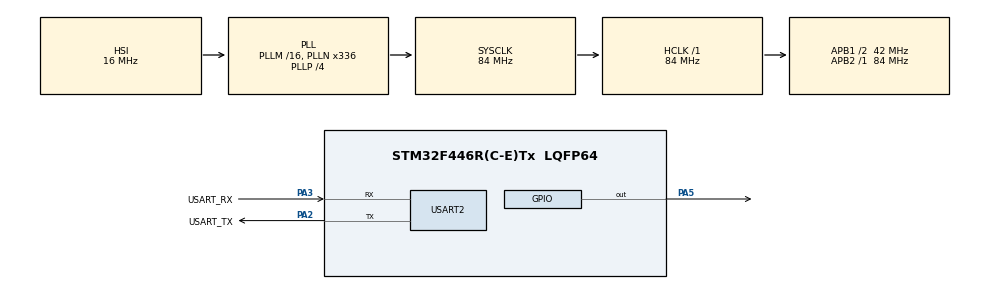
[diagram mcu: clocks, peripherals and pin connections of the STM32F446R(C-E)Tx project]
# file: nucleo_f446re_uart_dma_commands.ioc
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ADC1.Channel-0\#ChannelRegularConversion=ADC_CHANNEL_TEMPSENSOR
ADC1.DMAContinuousRequests=ENABLE
ADC1.ExternalTrigConv=ADC_EXTERNALTRIGCONV_T2_TRGO
ADC1.NbrOfConversionFlag=1
ADC1.Rank-0\#ChannelRegularConversion=1
ADC1.SamplingTime-0\#ChannelRegularConversion=ADC_SAMPLETIME_480CYCLES
ADC1.master=1
Dma.ADC1.2.Direction=DMA_PERIPH_TO_MEMORY
Dma.ADC1.2.FIFOMode=DMA_FIFOMODE_DISABLE
Dma.ADC1.2.Instance=DMA2_Stream0
Dma.ADC1.2.MemDataAlignment=DMA_MDATAALIGN_HALFWORD
Dma.ADC1.2.MemInc=DMA_MINC_ENABLE
Dma.ADC1.2.Mode=DMA_CIRCULAR
Dma.ADC1.2.PeriphDataAlignment=DMA_PDATAALIGN_HALFWORD
Dma.ADC1.2.PeriphInc=DMA_PINC_DISABLE
Dma.ADC1.2.Priority=DMA_PRIORITY_LOW
Dma.Request0=USART2_RX
Dma.Request1=USART2_TX
Dma.Request2=ADC1
Dma.USART2_RX.0.Direction=DMA_PERIPH_TO_MEMORY
Dma.USART2_RX.0.FIFOMode=DMA_FIFOMODE_DISABLE
Dma.USART2_RX.0.Instance=DMA1_Stream5
Dma.USART2_RX.0.MemDataAlignment=DMA_MDATAALIGN_BYTE
Dma.USART2_RX.0.MemInc=DMA_MINC_ENABLE
Dma.USART2_RX.0.Mode=DMA_CIRCULAR
Dma.USART2_RX.0.PeriphDataAlignment=DMA_PDATAALIGN_BYTE
Dma.USART2_RX.0.PeriphInc=DMA_PINC_DISABLE
Dma.USART2_RX.0.Priority=DMA_PRIORITY_HIGH
Dma.USART2_TX.1.Direction=DMA_MEMORY_TO_PERIPH
Dma.USART2_TX.1.FIFOMode=DMA_FIFOMODE_DISABLE
Dma.USART2_TX.1.Instance=DMA1_Stream6
Dma.USART2_TX.1.MemDataAlignment=DMA_MDATAALIGN_BYTE
Dma.USART2_TX.1.MemInc=DMA_MINC_ENABLE
Dma.USART2_TX.1.Mode=DMA_NORMAL
Dma.USART2_TX.1.PeriphDataAlignment=DMA_PDATAALIGN_BYTE
Dma.USART2_TX.1.PeriphInc=DMA_PINC_DISABLE
Dma.USART2_TX.1.Priority=DMA_PRIORITY_HIGH
FREERTOS.Mutexes01=sensorMutex,Dynamic,NULL,Available
FREERTOS.Queues01=uartRxQueue,128,uint8_t,0,Dynamic,NULL,NULL
FREERTOS.Tasks01=defaultTask,24,512,StartDefaultTask,Default,NULL,Dynamic,NULL,NULL;blinkTask,24,256,StartBlinkTask,Default,NULL,Dynamic,NULL,NULL;sensorTask,24,256,StartSensorTask,Default,NULL,Dynamic,NULL,NULL
FREERTOS.configCHECK_FOR_STACK_OVERFLOW=2
FREERTOS.configLIBRARY_LOWEST_INTERRUPT_PRIORITY=15
FREERTOS.configUSE_NEWLIB_REENTRANT=1
Mcu.Family=STM32F4
Mcu.Name=STM32F446R(C-E)Tx
Mcu.Package=LQFP64
NUCLEO-F446RE.LD1=true
NVIC.DMA1_Stream5_IRQn=true\:5\:0\:false\:false\:true\:true\:false\:true\:true
NVIC.DMA1_Stream6_IRQn=true\:5\:0\:false\:false\:true\:true\:false\:true\:true
NVIC.DMA2_Stream0_IRQn=true\:5\:0\:false\:false\:true\:true\:false\:true\:true
NVIC.PriorityGroup=NVIC_PRIORITYGROUP_4
NVIC.TIM6_DAC_IRQn=true\:15\:0\:false\:false\:true\:false\:false\:true\:true
NVIC.TimeBase=TIM6_DAC_IRQn
NVIC.TimeBaseIP=TIM6
NVIC.USART2_IRQn=true\:5\:0\:false\:false\:true\:true\:true\:true\:true
PA13.GPIO_Label=TMS
PA13.Mode=Serial_Wire
PA13.Signal=SYS_JTMS-SWDIO
PA14.GPIO_Label=TCK
PA14.Mode=Serial_Wire
PA14.Signal=SYS_JTCK-SWCLK
PA2.GPIO_Label=USART_TX
PA2.Mode=Asynchronous
PA2.Signal=USART2_TX
PA3.GPIO_Label=USART_RX
PA3.Mode=Asynchronous
PA3.Signal=USART2_RX
PA5.Signal=GPIO_Output
PB3.GPIO_Label=SWO
PB3.Signal=SYS_JTDO-SWO
PC14-OSC32_IN.Signal=RCC_OSC32_IN
PC15-OSC32_OUT.Signal=RCC_OSC32_OUT
PH0-OSC_IN.Signal=RCC_OSC_IN
PH1-OSC_OUT.Signal=RCC_OSC_OUT
ProjectManager.HeapSize=0x200
ProjectManager.StackSize=0x400
ProjectManager.TargetToolchain=STM32CubeIDE
RCC.AHBFreq_Value=84000000
RCC.APB1CLKDivider=RCC_HCLK_DIV2
RCC.APB1Freq_Value=42000000
RCC.APB1TimFreq_Value=84000000
RCC.APB2Freq_Value=84000000
RCC.APB2TimFreq_Value=84000000
RCC.CortexFreq_Value=84000000
RCC.FLatency-AdvancedSettings=FLASH_LATENCY_2
RCC.HCLKFreq_Value=84000000
RCC.HSE_VALUE=8000000
RCC.HSI_VALUE=16000000
RCC.LSE_VALUE=32768
RCC.PLLN=336
RCC.PLLP=RCC_PLLP_DIV4
RCC.SYSCLKFreq_VALUE=84000000
RCC.SYSCLKSource=RCC_SYSCLKSOURCE_PLLCLK
RCC.USBFreq_Value=168000000
RCC.VCOOutputFreq_Value=336000000
TIM2.Period=999
TIM2.Prescaler=8399
TIM2.TIM_MasterOutputTrigger=TIM_TRGO_UPDATE
USART2.VirtualMode=VM_ASYNC
VP_ADC1_TempSens_Input.Mode=IN-TempSens
VP_FREERTOS_VS_CMSIS_V2.Mode=CMSIS_V2
VP_NUCLEO-F446RE_VS_BSP_COMMON.Mode=COMMON
VP_SYS_VS_tim6.Mode=TIM6
VP_TIM2_VS_ClockSourceINT.Mode=Internal
board=NUCLEO-F446RE

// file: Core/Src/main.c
/* USER CODE BEGIN Header */
/**
  ******************************************************************************
  * @file           : main.c
  * @brief          : Main program body
  ******************************************************************************
  * @attention
  *
  * Copyright (c) 2026 STMicroelectronics.
  * All rights reserved.
  *
  * This software is licensed under terms that can be found in the LICENSE file
  * in the root directory of this software component.
  * If no LICENSE file comes with this software, it is provided AS-IS.
  *
  ******************************************************************************
  */
/* USER CODE END Header */
#include "main.h"
#include "cmsis_os.h"

/* USER CODE BEGIN Includes */

#include <stdbool.h>
#include <string.h>
#include "stm32f4xx_nucleo.h"
#include <stdio.h>
#include <stdlib.h>

/* USER CODE END Includes */

/* USER CODE BEGIN PTD */

typedef struct {
	uint32_t magic;
	uint32_t version;
	uint32_t blink_period_ms;
	uint32_t sample_period_ms;
	uint32_t checksum;
} app_config_t;

typedef struct {
	uint16_t raw;
	int32_t temp_x10;
	int32_t avg_x10;
	uint32_t processed;
	uint32_t timeouts;
} sensor_snapshot_t;

_Static_assert(sizeof(app_config_t) == 20, "app_config_t size changed, check Flash layout and checksum range");

/* USER CODE END PTD */

/* USER CODE BEGIN PD */

#define CONFIG_FLASH_ADDRESS 0x08060000u
#define CONFIG_FLASH_SECTOR FLASH_SECTOR_7
#define CONFIG_MAGIC 0x20040203u
#define CONFIG_VERSION 2u
#define BLINK_DEFAULT_MS 500u

#define ADC_DMA_BUFFER_LENGTH 1u
#define TS_CAL1_ADDRESS 0x1FFF7A2Cu
#define TS_CAL2_ADDRESS 0x1FFF7A2Eu
#define TS_CAL1_TEMP_C 30
#define TS_CAL2_TEMP_C 110

#define SAMPLE_MIN_PERIOD_MS 100u
#define SAMPLE_MAX_PERIOD_MS 10000u
#define SAMPLE_DEFAULT_PERIOD_MS 100u

#define BLINK_FLAG_UPDATE 0x01u
/*
 * Depends on TIM Prescaler = 8399 and Timer clock = 84 MHz.
 * 84 MHz / (8399 + 1) = 10 kHz, so 1 ms = 10 ticks.
 * This value is NOT updated automatically. If the Prescaler or the
 * clock tree is changed in CubeMX, recalculate and update it manually.
 */
#define TIM_TICKS_PER_MS 10u

#define SENSOR_FLAG_NEW_SAMPLE 0x01u
#define TEMP_AVG_LENGTH 8u
#define SENSOR_TIMEOUT_MS SAMPLE_MAX_PERIOD_MS * 2u

/* USER CODE END PD */

ADC_HandleTypeDef hadc1;
DMA_HandleTypeDef hdma_adc1;

TIM_HandleTypeDef htim2;

UART_HandleTypeDef huart2;
DMA_HandleTypeDef hdma_usart2_rx;
DMA_HandleTypeDef hdma_usart2_tx;

/* Definitions for defaultTask */
osThreadId_t defaultTaskHandle;
const osThreadAttr_t defaultTask_attributes = {
  .name = "defaultTask",
  .stack_size = 512 * 4,
  .priority = (osPriority_t) osPriorityNormal,
};
/* Definitions for blinkTask */
osThreadId_t blinkTaskHandle;
const osThreadAttr_t blinkTask_attributes = {
  .name = "blinkTask",
  .stack_size = 256 * 4,
  .priority = (osPriority_t) osPriorityNormal,
};
/* Definitions for sensorTask */
osThreadId_t sensorTaskHandle;
const osThreadAttr_t sensorTask_attributes = {
  .name = "sensorTask",
  .stack_size = 256 * 4,
  .priority = (osPriority_t) osPriorityNormal,
};
/* Definitions for uartRxQueue */
osMessageQueueId_t uartRxQueueHandle;
const osMessageQueueAttr_t uartRxQueue_attributes = {
  .name = "uartRxQueue"
};
/* Definitions for sensorMutex */
osMutexId_t sensorMutexHandle;
const osMutexAttr_t sensorMutex_attributes = {
  .name = "sensorMutex"
};
/* USER CODE BEGIN PV */

#define UART_DMA_RX_CAPACITY 64u
#define UART_COMMAND_CAPACITY 32u

static uint8_t uart_dma_rx[UART_DMA_RX_CAPACITY];
static volatile uint16_t uart_dma_last_position = 0u;

static volatile uint8_t uart_ring_overflow = 0u;

static char uart_command[UART_COMMAND_CAPACITY];
static uint16_t uart_command_len = 0u;
static uint8_t uart_discard_command = 0u;
static uint8_t uart_last_was_cr = 0u;

static bool led_is_on = false;

#define UART_TX_RING_CAPACITY 512u

static uint8_t uart_tx_ring[UART_TX_RING_CAPACITY];
static volatile uint16_t uart_tx_head = 0u;
static volatile uint16_t uart_tx_tail = 0u;

static volatile uint16_t uart_tx_dma_len = 0u;
static volatile uint8_t uart_tx_dma_active = 0u;

static volatile uint32_t uart_tx_dropped_messages = 0u;
static volatile uint32_t uart_rx_events = 0u;
static volatile uint32_t uart_rx_dropped_byte = 0u;
static volatile uint32_t uart_rx_command_overflows = 0u;

#define BLINK_MIN_PERIOD_MS 100u
#define BLINK_MAX_PERIOD_MS 2000u

static volatile bool blink_enable = false;
static volatile uint32_t blink_period_ms = BLINK_DEFAULT_MS;
static uint32_t last_blink_ms = 0u;

static bool config_loaded_from_flash = false;

static volatile uint16_t adc_dma_buffer[ADC_DMA_BUFFER_LENGTH] = {0};
static volatile uint32_t adc_sample_count = 0u;

static uint32_t sample_period_ms = SAMPLE_DEFAULT_PERIOD_MS;

static sensor_snapshot_t sensor_snapshot = {0};

/* USER CODE END PV */

void SystemClock_Config(void);
static void MX_GPIO_Init(void);
static void MX_DMA_Init(void);
static void MX_USART2_UART_Init(void);
static void MX_ADC1_Init(void);
static void MX_TIM2_Init(void);
void StartDefaultTask(void *argument);
void StartBlinkTask(void *argument);
void StartSensorTask(void *argument);

/* USER CODE BEGIN PFP */

static void uart_send_text(const char *text);
static void set_led(bool on);
static void process_command(const char *command);
static void process_uart_byte(uint8_t byte);

static void uart_ring_push(uint8_t byte);

static void uart_tx_kick_locked(void);
static uint16_t uart_tx_free_space_locked(void);

static void send_status(void);

static void send_stats(void);
static void reset_stats(void);

static uint32_t config_calculate_checksum(const app_config_t *config);
static bool config_is_valid(const app_config_t *config);
static void config_load(void);
static void send_config(void);
static bool config_save(void);
static bool config_erase(void);

static void split_temp_x10(int32_t t, const char **sign, uint32_t *int_part, uint32_t *frac_part);
static void send_adc(void);
static int32_t adc_raw_to_temperature_x10(uint16_t raw);

static void sample_apply_period(uint32_t ms);

static void sensor_publish(const sensor_snapshot_t *s);

/* USER CODE END PFP */

int main(void)
{

  /* MCU Configuration--------------------------------------------------------*/

  /* Reset of all peripherals, Initializes the Flash interface and the Systick. */
  HAL_Init();

  /* Configure the system clock */
  SystemClock_Config();

  /* Initialize all configured peripherals */
  MX_GPIO_Init();
  MX_DMA_Init();
  MX_USART2_UART_Init();
  MX_ADC1_Init();
  MX_TIM2_Init();
  /* USER CODE BEGIN 2 */

  set_led(false);
  config_load();

  if (HAL_UARTEx_ReceiveToIdle_DMA(&huart2, uart_dma_rx, UART_DMA_RX_CAPACITY) != HAL_OK)
	  Error_Handler();

  if (HAL_ADC_Start_DMA(&hadc1, (uint32_t *)adc_dma_buffer, ADC_DMA_BUFFER_LENGTH) != HAL_OK)
	  Error_Handler();

  sample_apply_period(sample_period_ms);

  last_blink_ms = HAL_GetTick();

  uart_send_text("\r\nUART DMA command controller ready\r\n");
  uart_send_text("Commands Details, Type 'HELP'\r\n");
  uart_send_text(config_loaded_from_flash ? "Config: loaded from flash\r\n> " : "Config: using defaults\r\n> ");

  /* USER CODE END 2 */

  /* Init scheduler */
  osKernelInitialize();
  /* Create the mutex(es) */
  /* creation of sensorMutex */
  sensorMutexHandle = osMutexNew(&sensorMutex_attributes);

  /* Create the queue(s) */
  /* creation of uartRxQueue */
  uartRxQueueHandle = osMessageQueueNew (128, sizeof(uint8_t), &uartRxQueue_attributes);

  /* Create the thread(s) */
  /* creation of defaultTask */
  defaultTaskHandle = osThreadNew(StartDefaultTask, NULL, &defaultTask_attributes);

  /* creation of blinkTask */
  blinkTaskHandle = osThreadNew(StartBlinkTask, NULL, &blinkTask_attributes);

  /* creation of sensorTask */
  sensorTaskHandle = osThreadNew(StartSensorTask, NULL, &sensorTask_attributes);

  /* Initialize leds */
  BSP_LED_Init(LED2);

  /* Start scheduler */
  osKernelStart();

  /* We should never get here as control is now taken by the scheduler */

  /* Infinite loop */
  while (1)
  {

  }
}

void SystemClock_Config(void)
{
  RCC_OscInitTypeDef RCC_OscInitStruct = {0};
  RCC_ClkInitTypeDef RCC_ClkInitStruct = {0};

  /** Configure the main internal regulator output voltage
  */
  __HAL_RCC_PWR_CLK_ENABLE();
  __HAL_PWR_VOLTAGESCALING_CONFIG(PWR_REGULATOR_VOLTAGE_SCALE3);

  /** Initializes the RCC Oscillators according to the specified parameters
  * in the RCC_OscInitTypeDef structure.
  */
  RCC_OscInitStruct.OscillatorType = RCC_OSCILLATORTYPE_HSI;
  RCC_OscInitStruct.HSIState = RCC_HSI_ON;
  RCC_OscInitStruct.HSICalibrationValue = RCC_HSICALIBRATION_DEFAULT;
  RCC_OscInitStruct.PLL.PLLState = RCC_PLL_ON;
  RCC_OscInitStruct.PLL.PLLSource = RCC_PLLSOURCE_HSI;
  RCC_OscInitStruct.PLL.PLLM = 16;
  RCC_OscInitStruct.PLL.PLLN = 336;
  RCC_OscInitStruct.PLL.PLLP = RCC_PLLP_DIV4;
  RCC_OscInitStruct.PLL.PLLQ = 2;
  RCC_OscInitStruct.PLL.PLLR = 2;
  if (HAL_RCC_OscConfig(&RCC_OscInitStruct) != HAL_OK)
  {
    Error_Handler();
  }

  /** Initializes the CPU, AHB and APB buses clocks
  */
  RCC_ClkInitStruct.ClockType = RCC_CLOCKTYPE_HCLK|RCC_CLOCKTYPE_SYSCLK
                              |RCC_CLOCKTYPE_PCLK1|RCC_CLOCKTYPE_PCLK2;
  RCC_ClkInitStruct.SYSCLKSource = RCC_SYSCLKSOURCE_PLLCLK;
  RCC_ClkInitStruct.AHBCLKDivider = RCC_SYSCLK_DIV1;
  RCC_ClkInitStruct.APB1CLKDivider = RCC_HCLK_DIV2;
  RCC_ClkInitStruct.APB2CLKDivider = RCC_HCLK_DIV1;

  if (HAL_RCC_ClockConfig(&RCC_ClkInitStruct, FLASH_LATENCY_2) != HAL_OK)
  {
    Error_Handler();
  }
}

static void MX_ADC1_Init(void)
{

  ADC_ChannelConfTypeDef sConfig = {0};

  /** Configure the global features of the ADC (Clock, Resolution, Data Alignment and number of conversion)
  */
  hadc1.Instance = ADC1;
  hadc1.Init.ClockPrescaler = ADC_CLOCK_SYNC_PCLK_DIV4;
  hadc1.Init.Resolution = ADC_RESOLUTION_12B;
  hadc1.Init.ScanConvMode = DISABLE;
  hadc1.Init.ContinuousConvMode = DISABLE;
  hadc1.Init.DiscontinuousConvMode = DISABLE;
  hadc1.Init.ExternalTrigConvEdge = ADC_EXTERNALTRIGCONVEDGE_RISING;
  hadc1.Init.ExternalTrigConv = ADC_EXTERNALTRIGCONV_T2_TRGO;
  hadc1.Init.DataAlign = ADC_DATAALIGN_RIGHT;
  hadc1.Init.NbrOfConversion = 1;
  hadc1.Init.DMAContinuousRequests = ENABLE;
  hadc1.Init.EOCSelection = ADC_EOC_SINGLE_CONV;
  if (HAL_ADC_Init(&hadc1) != HAL_OK)
  {
    Error_Handler();
  }

  /** Configure for the selected ADC regular channel its corresponding rank in the sequencer and its sample time.
  */
  sConfig.Channel = ADC_CHANNEL_TEMPSENSOR;
  sConfig.Rank = 1;
  sConfig.SamplingTime = ADC_SAMPLETIME_480CYCLES;
  if (HAL_ADC_ConfigChannel(&hadc1, &sConfig) != HAL_OK)
  {
    Error_Handler();
  }

}

static void MX_TIM2_Init(void)
{

  TIM_ClockConfigTypeDef sClockSourceConfig = {0};
  TIM_MasterConfigTypeDef sMasterConfig = {0};

  htim2.Instance = TIM2;
  htim2.Init.Prescaler = 8399;
  htim2.Init.CounterMode = TIM_COUNTERMODE_UP;
  htim2.Init.Period = 999;
  htim2.Init.ClockDivision = TIM_CLOCKDIVISION_DIV1;
  htim2.Init.AutoReloadPreload = TIM_AUTORELOAD_PRELOAD_DISABLE;
  if (HAL_TIM_Base_Init(&htim2) != HAL_OK)
  {
    Error_Handler();
  }
  sClockSourceConfig.ClockSource = TIM_CLOCKSOURCE_INTERNAL;
  if (HAL_TIM_ConfigClockSource(&htim2, &sClockSourceConfig) != HAL_OK)
  {
    Error_Handler();
  }
  sMasterConfig.MasterOutputTrigger = TIM_TRGO_UPDATE;
  sMasterConfig.MasterSlaveMode = TIM_MASTERSLAVEMODE_DISABLE;
  if (HAL_TIMEx_MasterConfigSynchronization(&htim2, &sMasterConfig) != HAL_OK)
  {
    Error_Handler();
  }

}

static void MX_USART2_UART_Init(void)
{

  huart2.Instance = USART2;
  huart2.Init.BaudRate = 115200;
  huart2.Init.WordLength = UART_WORDLENGTH_8B;
  huart2.Init.StopBits = UART_STOPBITS_1;
  huart2.Init.Parity = UART_PARITY_NONE;
  huart2.Init.Mode = UART_MODE_TX_RX;
  huart2.Init.HwFlowCtl = UART_HWCONTROL_NONE;
  huart2.Init.OverSampling = UART_OVERSAMPLING_16;
  if (HAL_UART_Init(&huart2) != HAL_OK)
  {
    Error_Handler();
  }

}

static void MX_DMA_Init(void)
{

  /* DMA controller clock enable */
  __HAL_RCC_DMA1_CLK_ENABLE();
  __HAL_RCC_DMA2_CLK_ENABLE();

  /* DMA interrupt init */
  /* DMA1_Stream5_IRQn interrupt configuration */
  HAL_NVIC_SetPriority(DMA1_Stream5_IRQn, 5, 0);
  HAL_NVIC_EnableIRQ(DMA1_Stream5_IRQn);
  /* DMA1_Stream6_IRQn interrupt configuration */
  HAL_NVIC_SetPriority(DMA1_Stream6_IRQn, 5, 0);
  HAL_NVIC_EnableIRQ(DMA1_Stream6_IRQn);
  /* DMA2_Stream0_IRQn interrupt configuration */
  HAL_NVIC_SetPriority(DMA2_Stream0_IRQn, 5, 0);
  HAL_NVIC_EnableIRQ(DMA2_Stream0_IRQn);

}

static void MX_GPIO_Init(void)
{

  /* GPIO Ports Clock Enable */
  __HAL_RCC_GPIOC_CLK_ENABLE();
  __HAL_RCC_GPIOH_CLK_ENABLE();
  __HAL_RCC_GPIOA_CLK_ENABLE();
  __HAL_RCC_GPIOB_CLK_ENABLE();

}

/* USER CODE BEGIN 4 */

void HAL_UARTEx_RxEventCallback(UART_HandleTypeDef *huart, uint16_t size) {
	uint16_t new_position;
	uint16_t index;

	if (huart->Instance != USART2)
		return;

	uart_rx_events++;

	new_position = (uint16_t)(size % UART_DMA_RX_CAPACITY);

	if (new_position > uart_dma_last_position) {
		for (index = uart_dma_last_position; index < new_position; index++)
			uart_ring_push(uart_dma_rx[index]);
	}
	else if (new_position < uart_dma_last_position) {
		for (index = uart_dma_last_position; index < UART_DMA_RX_CAPACITY; index++)
			uart_ring_push(uart_dma_rx[index]);

		for (index = 0u; index < new_position; index++)
			uart_ring_push(uart_dma_rx[index]);
	}

	uart_dma_last_position = new_position;
}

static void uart_ring_push(uint8_t byte)
{
  if (osMessageQueuePut(uartRxQueueHandle, &byte, 0, 0) != osOK) {
	  uart_ring_overflow = 1u;
	  uart_rx_dropped_byte++;
  }

}

static void process_uart_byte(uint8_t byte)
{
  uint8_t last_was_cr = uart_last_was_cr;

  uart_last_was_cr = (byte == (uint8_t)'\r') ? 1u : 0u;

  if (byte == (uint8_t)'\n' && last_was_cr != 0u)
	  return;

  if (byte == (uint8_t)'\n' || byte == (uint8_t)'\r')
  {
    if (uart_discard_command != 0u)
    {
      uart_discard_command = 0u;
      uart_command_len = 0u;
      uart_send_text("ERROR: command too long\r\n> ");
      return;
    }

    uart_command[uart_command_len] = '\0';
    process_command(uart_command);
    uart_command_len = 0u;
    return;
  }

  if (uart_discard_command != 0u)
  {
    return;
  }

  if (uart_command_len < (UART_COMMAND_CAPACITY - 1u))
  {
    uart_command[uart_command_len] = (char)byte;
    uart_command_len++;
  }
  else
  {
    uart_discard_command = 1u;
    uart_rx_command_overflows++;
  }
}

static void process_command(const char *command)
{
	char *end_ptr;
	unsigned long requested_period;

	if(strcmp(command, "HELP") == 0)
	{
		uart_send_text("Commands:\r\n");
		uart_send_text(" LED ON\r\n");
		uart_send_text(" LED OFF\r\n");
		uart_send_text(" BLINK <100-2000>\r\n");
		uart_send_text(" BLINK OFF\r\n");
		uart_send_text(" STATUS\r\n");
		uart_send_text(" STATS\r\n");
		uart_send_text(" RESET STATS\r\n");
		uart_send_text(" CONFIG SHOW\r\n");
		uart_send_text(" CONFIG SAVE\r\n");
		uart_send_text(" CONFIG RESET\r\n");
		uart_send_text(" ADC\r\n");
		uart_send_text(" SAMPLE <100-10000>\r\n> ");
	}
	else if (strcmp(command, "LED ON") == 0)
	{
		blink_enable = false;
		set_led(true);
		osThreadFlagsSet(blinkTaskHandle, BLINK_FLAG_UPDATE);
		uart_send_text("OK: LED ON\r\n> ");
	}
	else if (strcmp(command, "LED OFF") == 0)
	{
		blink_enable = false;
		set_led(false);
		osThreadFlagsSet(blinkTaskHandle, BLINK_FLAG_UPDATE);
		uart_send_text("OK: LED OFF\r\n> ");
	}
	else if (strcmp(command, "STATUS") == 0)
	{
		send_status();
	}
	else if (strcmp(command, "STATS") == 0)
	{
		send_stats();
	}
	else if (strcmp(command, "RESET STATS") == 0)
	{
		reset_stats();
	}
	else if (strcmp(command, "CONFIG SHOW") == 0)
	{
		send_config();
	}
	else if (strcmp(command, "CONFIG SAVE") == 0)
	{
		if (config_save())
			uart_send_text("OK: config saved\r\n> ");
		else
			uart_send_text("ERROR: flash save failed\r\n> ");
	}
	else if (strcmp(command, "CONFIG RESET") == 0)
	{
		if (config_erase()){
			blink_period_ms = BLINK_DEFAULT_MS;
			config_loaded_from_flash = false;
			sample_period_ms = SAMPLE_DEFAULT_PERIOD_MS;
			sample_apply_period(sample_period_ms);
			uart_send_text("OK: config reset to defaults\r\n> ");
		}
		else
			uart_send_text("ERROR: flash erase failed\r\n> ");
	}
	else if (strcmp(command, "ADC") == 0)
	{
			send_adc();
	}
	else if (strcmp(command, "BLINK OFF") == 0)
	{
		blink_enable = false;
		osThreadFlagsSet(blinkTaskHandle, BLINK_FLAG_UPDATE);
		uart_send_text("OK: blink disabled\r\n> ");
	}
	else if (strncmp(command, "BLINK ", 6u) == 0)
	{
		requested_period = strtoul(&command[6], &end_ptr, 10);

		if ((*end_ptr != '\0') || (requested_period < BLINK_MIN_PERIOD_MS) || (requested_period > BLINK_MAX_PERIOD_MS))
		{
			uart_send_text("ERROR: use BLINK <100-2000> or BLINK OFF\r\n> ");
			return;
		}

		blink_period_ms = requested_period;
		last_blink_ms = HAL_GetTick();
		blink_enable = true;
		osThreadFlagsSet(blinkTaskHandle, BLINK_FLAG_UPDATE);

		uart_send_text("OK: blink enable\r\n> ");
	}
	else if(strncmp(command, "SAMPLE ", 7u) == 0) {
		requested_period = strtoul(&command[7], &end_ptr, 10);

		if ((*end_ptr != '\0') || (requested_period < SAMPLE_MIN_PERIOD_MS) || (requested_period > SAMPLE_MAX_PERIOD_MS))
		{
			uart_send_text("ERROR: use SAMPLE <100-10000>\r\n> ");
			return;
		}
		else
		{
			sample_period_ms = requested_period;
			sample_apply_period(requested_period);
			uart_send_text("OK: Sample Applied\r\n> ");
		}
	}
	else if (command[0] == '\0')
	{
		uart_send_text("> ");
	}
	else
	{
		uart_send_text("ERROR: unknown command; type HELP\r\n> ");
	}
}

static void set_led(bool on)
{
  if (on)
  {
    BSP_LED_On(LED2);
  }
  else
  {
    BSP_LED_Off(LED2);
  }

  led_is_on = on;
}

static void uart_send_text(const char *text)
{
  uint32_t primask;
  size_t len;
  uint16_t index;

  len = strlen(text);

  /*
   *
   * Every response in this project is much shorter than 255 bytes.
   * Refuse messages that can never fit in the ring.
   */
  if (len == 0u || len >= UART_TX_RING_CAPACITY) return;

  /*
   *
   * The main loop modified head while the UART-complete ISR modified tail.
   * Protect the check, enqueue, and DMA-start operation as one transaction.
   */
  primask = __get_PRIMASK();
  __disable_irq();

  if ((uint16_t)len > uart_tx_free_space_locked())
	  uart_tx_dropped_messages++;
  else {
	  for (index = 0u; index < (uint16_t)len; index++) {
		  uart_tx_ring[uart_tx_head] = (uint8_t)text[index];
		  uart_tx_head = (uint16_t)(uart_tx_head + 1u) % UART_TX_RING_CAPACITY;
	  }

	  uart_tx_kick_locked();
  }

  if (primask == 0u) __enable_irq();
}

static uint16_t uart_tx_free_space_locked(void) {
	uint16_t used;

	if (uart_tx_head >= uart_tx_tail)
		used = (uint16_t)(uart_tx_head - uart_tx_tail);
	else
		used = (uint16_t)(UART_TX_RING_CAPACITY - (uart_tx_tail - uart_tx_head));

	return (uint16_t)((UART_TX_RING_CAPACITY - 1u) - used);
}

static void uart_tx_kick_locked(void) {
	uint16_t contiguous_len;

	if ((uart_tx_dma_active != 0u) || (uart_tx_head == uart_tx_tail)) return;

	/*
	 *
	 * DMA can only read one contiguous memory range at a time.
	 * if the queued message wraps around the end of ring, send
	 * the tail-to-end segment now; TxCpltCallback starts the next one.
	 */
	if (uart_tx_head > uart_tx_tail)
		contiguous_len = (uint16_t)(uart_tx_head - uart_tx_tail);
	else
		contiguous_len = (uint16_t)(UART_TX_RING_CAPACITY - uart_tx_tail);

	uart_tx_dma_len = contiguous_len;
	uart_tx_dma_active = 1u;

	if (HAL_UART_Transmit_DMA(&huart2, &uart_tx_ring[uart_tx_tail], contiguous_len) != HAL_OK) {
		/*
		 *
		 * Keep the queued data intact. A later call to uart_send_text()
		 * can retry starting TX after transient HAL_BUSY conditions.
		 */
		uart_tx_dma_active = 0u;
		uart_tx_dma_len = 0u;
	}
}

void HAL_UART_TxCpltCallback(UART_HandleTypeDef *huart) {
	if (huart->Instance != USART2) return;

	/*
	 * The DMA transfer fully complete, so its ring-buffer region
	 * may now be reused by future responses.
	 */
	uart_tx_tail = (uint16_t)(uart_tx_tail + uart_tx_dma_len) % UART_TX_RING_CAPACITY;

	uart_tx_dma_len = 0u;
	uart_tx_dma_active = 0u;

	/*
	 *
	 * Start the next contiguous queued segment, if any.
	 * This callback already runs in interrupt context.
	 */
	uart_tx_kick_locked();
}

static void send_status(void) {
	char response[96];

	if (blink_enable) {
		(void)snprintf(response,
					   sizeof(response),
					   "STATUS: LED %s, BLINK ON (%lu ms)\r\n> ",
					   led_is_on ? "ON" : "OFF", (unsigned long)blink_period_ms);
	}
	else {
		(void)snprintf(response, sizeof(response),
						"STATUS: LED %s, BLINK OFF\r\n> ",
						led_is_on ? "ON" : "OFF");
	}

	uart_send_text(response);
}

static void send_stats(void) {
	char response[192];
	uint32_t uptime_ms = HAL_GetTick();

	(void)snprintf(response,
				   sizeof(response),
				   "STATS: uptime=%lu ms, RX events=%lu, RX dropped bytes=%lu, RX command overflows=%lu, TX dropped messages=%lu\r\n> ",
				   (unsigned long)uptime_ms,
				   (unsigned long)uart_rx_events,
				   (unsigned long)uart_rx_dropped_byte,
				   (unsigned long)uart_rx_command_overflows,
				   (unsigned long)uart_tx_dropped_messages);

	uart_send_text(response);
}

static void reset_stats(void) {
	uint32_t primask;

	primask = __get_PRIMASK();
	__disable_irq();

	uart_rx_events = 0u;
	uart_rx_dropped_byte = 0u;
	uart_rx_command_overflows = 0u;
	uart_tx_dropped_messages = 0u;

	if (primask == 0u) __enable_irq();

	uart_send_text("OK: stats reset\r\n> ");

}

static uint32_t config_calculate_checksum(const app_config_t *config) {
	return config->magic ^ config->blink_period_ms ^ config->version ^ config->sample_period_ms ^ 930203u;
}

static bool config_is_valid(const app_config_t *config) {
	if (config->magic != CONFIG_MAGIC)
		return false;
	else if (config->version != CONFIG_VERSION)
		return false;
	else if (config->checksum != config_calculate_checksum(config))
		return false;
	else if (config->blink_period_ms > BLINK_MAX_PERIOD_MS || config->blink_period_ms < BLINK_MIN_PERIOD_MS)
		return false;
	else if (config->sample_period_ms > SAMPLE_MAX_PERIOD_MS || config->sample_period_ms < SAMPLE_MIN_PERIOD_MS)
		return false;
	else
		return true;
}

static void config_load(void) {
	const app_config_t *config = (const app_config_t *)CONFIG_FLASH_ADDRESS;

	if (config_is_valid(config)) {
		blink_period_ms = config->blink_period_ms;
		sample_period_ms = config->sample_period_ms;
		config_loaded_from_flash = true;
	}

}

static void send_config(void) {
	char response[192];

	const app_config_t *config = (const app_config_t *)CONFIG_FLASH_ADDRESS;

	if (config_is_valid(config)) {
		(void)snprintf(response,
					   sizeof(response),
					   "Blink(Now)=%lu, Blink(In Flash)=%lu, Sample(Now)=%lu, Sample(In Flash)=%lu, Config Loaded From %s\r\n> ",
					   (unsigned long)blink_period_ms,
					   (unsigned long)config->blink_period_ms,
					   (unsigned long)sample_period_ms,
					   (unsigned long)config->sample_period_ms,
					   config_loaded_from_flash ? "Flash" : "Defaults");
	}
	else {
		(void)snprintf(response,
					   sizeof(response),
					   "Blink(Now)=%lu, Blink(In Flash)=%s, Sample(Now)=%lu, Sample(In Flash)=%s, Config Loaded From %s\r\n> ",
					   (unsigned long)blink_period_ms,
					   "None",
					   (unsigned long)sample_period_ms,
					   "None",
					   config_loaded_from_flash ? "Flash" : "Defaults");
	}

	uart_send_text(response);
}

static bool config_save(void) {
	app_config_t new_config;
	bool success = false;

	FLASH_EraseInitTypeDef EraseInitStruct = {0};
	uint32_t sector_error = 0u;
	HAL_StatusTypeDef status;

	uint32_t index;
	const uint32_t *words;

	new_config.magic = CONFIG_MAGIC;
	new_config.version = CONFIG_VERSION;
	new_config.blink_period_ms = blink_period_ms;
	new_config.sample_period_ms = sample_period_ms;
	new_config.checksum = config_calculate_checksum(&new_config);

	words = (const uint32_t *)&new_config;

	status = HAL_FLASH_Unlock();

	if (status == HAL_OK) {
		EraseInitStruct.TypeErase = FLASH_TYPEERASE_SECTORS;
		EraseInitStruct.Sector = CONFIG_FLASH_SECTOR;
		EraseInitStruct.NbSectors = 1u;
		EraseInitStruct.VoltageRange = FLASH_VOLTAGE_RANGE_3;

		status = HAL_FLASHEx_Erase(&EraseInitStruct, &sector_error);

		if (status == HAL_OK) {
			for (index = 0u; index < (sizeof(app_config_t) / sizeof(uint32_t)); index++) {
				status = HAL_FLASH_Program(FLASH_TYPEPROGRAM_WORD, CONFIG_FLASH_ADDRESS + index*4u, words[index]);
				if (status != HAL_OK) break;
			}
		}
	}

	HAL_FLASH_Lock();

	if (status == HAL_OK) {
		const app_config_t *stored = (const app_config_t *)CONFIG_FLASH_ADDRESS;
		if (config_is_valid(stored) && memcmp(stored, &new_config, sizeof(app_config_t)) == 0)
			success = true;
	}

	return success;
}

static bool config_erase(void) {
	bool success = false;

	FLASH_EraseInitTypeDef EraseInitStruct = {0};
	uint32_t sector_error = 0u;
	HAL_StatusTypeDef status;

	status = HAL_FLASH_Unlock();

	if (status == HAL_OK) {
		EraseInitStruct.TypeErase = FLASH_TYPEERASE_SECTORS;
		EraseInitStruct.Sector = CONFIG_FLASH_SECTOR;
		EraseInitStruct.NbSectors = 1u;
		EraseInitStruct.VoltageRange = FLASH_VOLTAGE_RANGE_3;

		status = HAL_FLASHEx_Erase(&EraseInitStruct, &sector_error);
	}

	HAL_FLASH_Lock();

	if (status == HAL_OK) {
		const app_config_t *stored = (const app_config_t *)CONFIG_FLASH_ADDRESS;
		if (!config_is_valid(stored))
			success = true;
	}

	return success;
}

void HAL_ADC_ConvCpltCallback(ADC_HandleTypeDef *hadc) {
	if (hadc->Instance == ADC1) {
		adc_sample_count++;
		osThreadFlagsSet(sensorTaskHandle, SENSOR_FLAG_NEW_SAMPLE);
	}
}

static void send_adc(void) {
	char response[160];

	sensor_snapshot_t send_data = {0};
	send_data = sensor_snapshot;

	uint16_t raw = send_data.raw;
	uint32_t samples = adc_sample_count;
	uint32_t processed = send_data.processed;
	uint32_t timeouts = send_data.timeouts;

	int32_t t = send_data.temp_x10;
	const char *t_sign;
	uint32_t t_int;
	uint32_t t_frac;

	int32_t avg = send_data.avg_x10;
	const char *avg_sign;
	uint32_t avg_int;
	uint32_t avg_frac;

	split_temp_x10(t, &t_sign, &t_int, &t_frac);
	split_temp_x10(avg, &avg_sign, &avg_int, &avg_frac);

	(void)snprintf(response,
				   sizeof(response),
				   "ADC: raw=%lu, temp=%s%lu.%lu degC, avg=%s%lu.%lu degC, samples=%lu, processed=%lu, timeouts=%lu\r\n> ",
				   (unsigned long)raw,
				   t_sign,
				   (unsigned long)t_int,
				   (unsigned long)t_frac,
				   avg_sign,
				   (unsigned long)avg_int,
				   (unsigned long)avg_frac,
				   (unsigned long)samples,
				   (unsigned long)processed,
				   (unsigned long)timeouts);

	uart_send_text(response);
}

static int32_t adc_raw_to_temperature_x10(uint16_t raw) {
	int32_t cal1 = *(const uint16_t *)TS_CAL1_ADDRESS;
	int32_t cal2 = *(const uint16_t *)TS_CAL2_ADDRESS;
	int32_t raw_s32 = (int32_t)raw;

	if (cal1 == cal2) return 0;

		return TS_CAL1_TEMP_C * 10 + ((TS_CAL2_TEMP_C - TS_CAL1_TEMP_C) * 10) * (raw_s32 - cal1) / (cal2 - cal1);
}

static void sample_apply_period(uint32_t ms) {
	uint32_t arr = (ms * TIM_TICKS_PER_MS) - 1;

	__HAL_TIM_SET_AUTORELOAD(&htim2, arr);

	__HAL_TIM_SET_COUNTER(&htim2, 0u);
}

static void split_temp_x10(int32_t t, const char **sign, uint32_t *int_part, uint32_t *frac_part) {
	uint32_t abs_t;

	if (t < 0) {
		*sign = "-";
		abs_t = -t;
	}
	else {
		*sign = "";
		abs_t = t;
	}

	*int_part = abs_t / 10;
	*frac_part = abs_t % 10;
}

static void sensor_publish(const sensor_snapshot_t *s) {
	osMutexAcquire(sensorMutexHandle, osWaitForever);
	sensor_snapshot = *s;
	osMutexRelease(sensorMutexHandle);
}

/* USER CODE END 4 */

void StartDefaultTask(void *argument)
{
  /* USER CODE BEGIN 5 */
  /* Infinite loop */
  uint8_t byte;
  for(;;)
  {
	  if (osMessageQueueGet(uartRxQueueHandle, &byte, NULL, osWaitForever) == osOK) {
		  if (uart_ring_overflow != 0u) {
		  	uart_ring_overflow = 0u;
		  	uart_command_len = 0u;
		  	uart_discard_command = 1u;
		  	uart_send_text("ERROR: receive buffer overflow\r\n> ");
		  }

		  process_uart_byte(byte);
	  }
  }
  /* USER CODE END 5 */
}

void StartBlinkTask(void *argument)
{
  /* USER CODE BEGIN StartBlinkTask */
  /* Infinite loop */
  for(;;)
  {
	  if (blink_enable) {
	  	set_led(!led_is_on);
	  	osThreadFlagsWait(BLINK_FLAG_UPDATE, osFlagsWaitAny, blink_period_ms);
	  }
	  else {
	  	osThreadFlagsWait(BLINK_FLAG_UPDATE, osFlagsWaitAny, osWaitForever);
	  }
  }
  /* USER CODE END StartBlinkTask */
}

void StartSensorTask(void *argument)
{
  /* USER CODE BEGIN StartSensorTask */
  /* Infinite loop */

	sensor_snapshot_t local = {0};

	int32_t temp_avg[TEMP_AVG_LENGTH] = {0};
	uint32_t current = 0u;
	uint32_t filled_cnt = 0u;
	int32_t sum	= 0;
	uint32_t flag = 0u;

	if (HAL_TIM_Base_Start(&htim2) != HAL_OK){
		Error_Handler();
	}

  for(;;)
  {
	  flag = osThreadFlagsWait(SENSOR_FLAG_NEW_SAMPLE, osFlagsWaitAny, SENSOR_TIMEOUT_MS);

	  if ((flag & osFlagsError) != 0u) {
		  local.timeouts++;
	  }
	  else {
		  uint16_t raw = adc_dma_buffer[0];
		  int32_t temp = adc_raw_to_temperature_x10(raw);
		  sum -= temp_avg[current];
		  sum += temp;
		  temp_avg[current] = temp;
		  current = (current + 1u) & (TEMP_AVG_LENGTH - 1u);

		  if (filled_cnt < TEMP_AVG_LENGTH){
			  filled_cnt++;
		  }

		  local.raw = raw;
		  local.temp_x10 = temp;
		  local.avg_x10 = sum / (int32_t)filled_cnt;
		  local.processed++;
	  }

	  sensor_publish(&local);
  }
  /* USER CODE END StartSensorTask */
}

void HAL_TIM_PeriodElapsedCallback(TIM_HandleTypeDef *htim)
{
  if (htim->Instance == TIM6)
  {
    HAL_IncTick();
  }
}

void Error_Handler(void)
{
  __disable_irq();
  while (1)
  {
  }
}

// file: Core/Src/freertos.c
/* USER CODE BEGIN Header */
/**
  ******************************************************************************
  * File Name          : freertos.c
  * Description        : Code for freertos applications
  ******************************************************************************
  * @attention
  *
  * Copyright (c) 2026 STMicroelectronics.
  * All rights reserved.
  *
  * This software is licensed under terms that can be found in the LICENSE file
  * in the root directory of this software component.
  * If no LICENSE file comes with this software, it is provided AS-IS.
  *
  ******************************************************************************
  */
/* USER CODE END Header */

#include "FreeRTOS.h"
#include "task.h"
#include "main.h"

/* Hook prototypes */
void vApplicationStackOverflowHook(xTaskHandle xTask, signed char *pcTaskName);

/* USER CODE BEGIN 4 */
void vApplicationStackOverflowHook(xTaskHandle xTask, signed char *pcTaskName)
{
   /* Run time stack overflow checking is performed if
   configCHECK_FOR_STACK_OVERFLOW is defined to 1 or 2. This hook function is
   called if a stack overflow is detected. */

	__disable_irq();
	while(1){

	}
}
/* USER CODE END 4 */
